AUTOSAR XML (schema 00046)
package /jmc_auto/PlatformServices/CanbusApplication
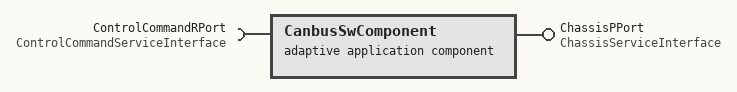
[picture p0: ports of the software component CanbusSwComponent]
  adaptive application sw component type CanbusSwComponent
    provide port ChassisPPort: provided-interface=ChassisServiceInterface
    require port ControlCommandRPort: required-interface=ControlCommandServiceInterface
package /jmc_auto/PlatformServices/CanbusExecutable
  executable CanbusExecutable
    root sw component prototype CanbusRootSwComponent: application-type=CanbusSwComponent
